# STM32WB5Mxx register map
File version: 1.0
Registers are 32-bit, read-write, reset 0x0 unless marked. A register's access mark holds for its fields unless they carry their own. Offsets are from the block's base; [hi:lo] are bit positions; {n}, {i} and the like mark numbered series.

## PWR — Power Control
Base 0x58000400
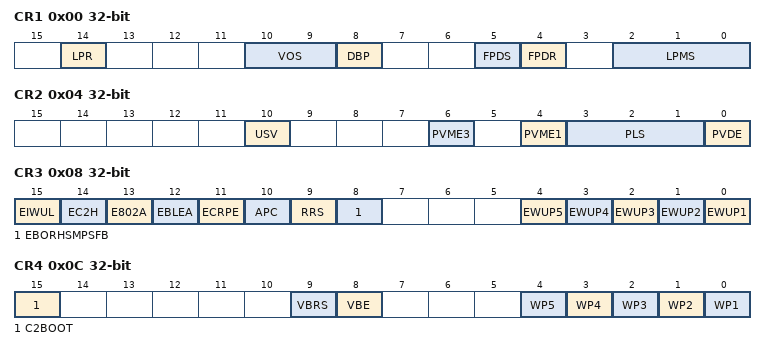
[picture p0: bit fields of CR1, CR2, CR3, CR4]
0x00 CR1 — PWR Power Control Register 1
  [14] LPR — Regulator Low-Power Run mode
  [10:9] VOS — Voltage scaling range selection
    1=SCALE1; 2=SCALE2
  [8] DBP — Disable Backup Domain write protection
  [5] FPDS — Flash power down mode during LPsleep for CPU1
    0=IDLE; 1=POWER_DOWN
  [4] FPDR — Flash power down mode during LPrun for CPU1
    0=IDLE; 1=POWER_DOWN
  [2:0] LPMS — Low Power Mode Selection for CPU1
    0=STOP0; 1=STOP1; 2=STOP2; 3=STANDBY; 4=SHUTDOWN
0x04 CR2 — PWR Power Control Register 2
  [10] USV — USB Supply Valid
  [6] PVME3 — Peripherical Voltage Monitor Vdda Enable
  [4] PVME1 — Peripherical Voltage Monitor Vusb Enable
  [3:1] PLS — Power voltage detector level selection
    {v}=PVDLEVEL_{v} (v=0..7)
  [0] PVDE — Power voltage detector enable
0x08 CR3 — PWR Power Control Register 3
  [15] EIWUL — Internal Wake-Up line interrupt for CPU1
  [14] EC2H — CPU2 Hold interrupt for CPU1
  [13] E802A — 802.15.4 end of activity interrupt for CPU1
  [12] EBLEA — BLE end of activity interrupt for CPU1
  [11] ECRPE — Critical radio phase end of activity interrupt for CPU1
  [10] APC — Apply pull-up and pull-down configuration for CPU1
  [9] RRS — SRAM2 retention in STANDBY mode
  [8] EBORHSMPSFB — BORH and SMPS Step Down converter forced in Bypass interrupts for CPU1
  [4] EWUP5 — Enable external WKUP Pin 5 [line 4]
  [3] EWUP4 — Enable external WKUP Pin 4 [line 3]
  [2] EWUP3 — Enable external WKUP Pin 3 [line 2]
  [1] EWUP2 — Enable external WKUP Pin 2 [line 1]
  [0] EWUP1 — Enable external WKUP Pin 1 [line 0]
0x0C CR4 — PWR Power Control Register 4
  [15] C2BOOT — Boot CPU2 after reset or wakeup from Stop or Standby modes
  [9] VBRS — VBAT battery charging resistor selection
    0=CHARG_RESISTOR_5K; 1=CHARGRESISTOR_1_5K
  [8] VBE — VBAT battery charging enable
  [4] WP5 — Wake-Up Pin 5 [line 4] polarity
  [3] WP4 — Wake-Up Pin 4 [line 3] polarity
  [2] WP3 — Wake-Up Pin 3 [line 2] polarity
  [1] WP2 — Wake-Up Pin 2 [line 1] polarity
  [0] WP1 — Wake-Up Pin 1 [line 0] polarity
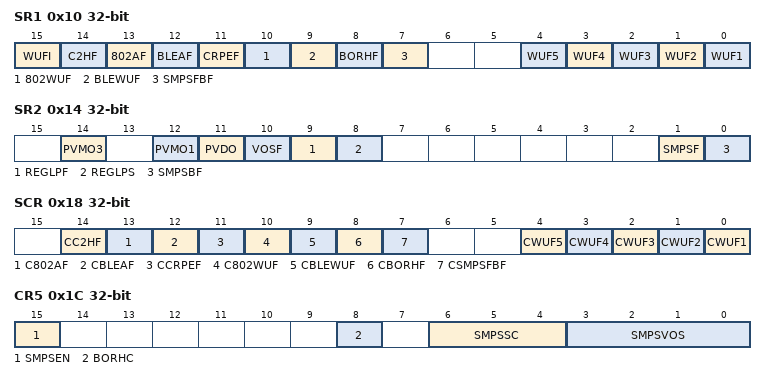
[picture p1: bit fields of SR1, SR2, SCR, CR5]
0x10 SR1 — PWR Power Status Register 1
  [15] WUFI — Internal wakeup interrupt flag
  [14] C2HF — CPU2 Hold interrupt flag
  [13] 802AF — 802.15.4 end of activity interrupt flag
  [12] BLEAF — BLE end of activity interrupt flag
  [11] CRPEF — Critical radio phase end of activity interrupt flag
  [10] 802WUF — 802.15.4 wakeup interrupt flag
  [9] BLEWUF — BLE wakeup interrupt flag
  [8] BORHF — BORH interrupt flag
  [7] SMPSFBF — SMPS Step Down converter forced in bypass mode interrupt flag
  [4] WUF5 — Wakeup Pin 5 [Flag 4]
  [3] WUF4 — Wakeup Pin 4 [Flag 3]
  [2] WUF3 — Wakeup Pin 3 [Flag 2]
  [1] WUF2 — Wakeup Pin 2 [Flag 1]
  [0] WUF1 — Wakeup Pin 1 [Flag 0]
0x14 SR2 — PWR Power Status Register 2
  [14] PVMO3 — Peripheral voltage monitor output 3: VDDA vs. 1.62V
  [12] PVMO1 — Peripheral voltage monitor output 1: VDDUSB vs. 1.2V
  [11] PVDO — Power voltage detector output
  [10] VOSF — Voltage scaling flag
  [9] REGLPF — Low-power regulator flag
  [8] REGLPS — Low-power regulator started
  [1] SMPSF — SMPS step down converter in operating mode step down flag
  [0] SMPSBF — SMPS step down converter in operating mode bypass flag
0x18 SCR — PWR Power Status Reset Register
  [14] CC2HF — Clear CPU2 Hold interrupt flag
  [13] C802AF — Clear 802.15.4 end of activity interrupt flag
  [12] CBLEAF — Clear BLE end of activity interrupt flag
  [11] CCRPEF — Clear Critical radio phase end of activity interrupt flag
  [10] C802WUF — Clear 802.15.4 wakeup interrupt flag
  [9] CBLEWUF — Clear BLE wakeup interrupt flag
  [8] CBORHF — Clear BORH interrupt flag
  [7] CSMPSFBF — Clear SMPS Step Down converter forced in bypass mode interrupt flag
  [4] CWUF5 — Clear Wake-up Pin 5 [Flag 4]
  [3] CWUF4 — Clear Wake-up Pin 4 [Flag 3]
  [2] CWUF3 — Clear Wake-up Pin 3 [Flag 2]
  [1] CWUF2 — Clear Wake-up Pin 2 [Flag 1]
  [0] CWUF1 — Clear Wake-up Pin 1 [Flag 0]
0x1C CR5 — PWR Power Control Register 5
  [15] SMPSEN — Enable SMPS Step Down converter SMPS mode enable
  [8] BORHC — BORH configuration selection
    0=SYSTEM_RESET (BOR will generate a system reset); 1=SMPS_FORCE_BYPASS (BOR will for SMPS step down converter in bypass mode)
  [6:4] SMPSSC — SMPS step down converter supply startup current selection
    0=CURRENT_80MA (SMPS step down converter supply startup current 80mA); 1=CURRENT_100MA (SMPS step down converter supply startup current 100mA); 2=CURRENT_120MA (SMPS step down converter supply startup current 120mA); 3=CURRENT_140MA (SMPS step down converter supply startup current 140mA); 4=CURRENT_160MA (SMPS step down converter supply startup current 160mA); 5=CURRENT_180MA (SMPS step down converter supply startup current 180mA); 6=CURRENT_200MA (SMPS step down converter supply startup current 200mA); 7=CURRENT_220MA (SMPS step down converter supply startup current 220mA)
  [3:0] SMPSVOS — SMPS step down converter voltage output scaling voltage level
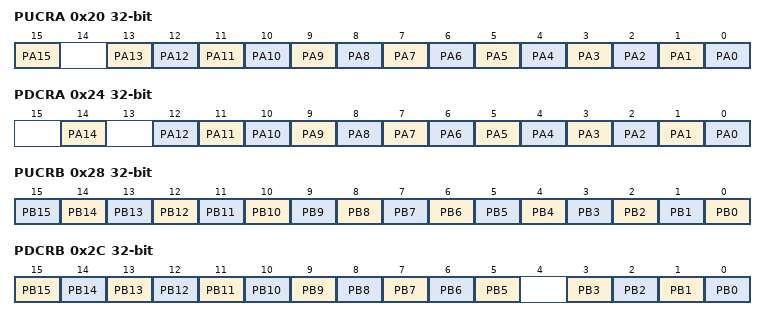
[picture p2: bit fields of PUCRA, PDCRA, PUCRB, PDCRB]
0x20 PUCRA — PWR Pull-Up Control Register of port A
  [15] PA15 — Pin PA15 Pull-Up set
  [n] PA{n} (n=0..13) — Pin PA{n} Pull-Up set
0x24 PDCRA — PWR Pull-Down Control Register of port A
  [14] PA14 — Pin PA14 Pull-Down set
  [n] PA{n} (n=0..12) — Pin PA{n} Pull-Down set
0x28 PUCRB — PWR Pull-Up Control Register of port B
  [n] PB{n} (n=0..15) — Pin PB{n} Pull-Up set
0x2C PDCRB — PWR Pull-Down Control Register of port B
  [n] PB{n} (n=5..15) — Pin PB{n} Pull-Down set
  [n] PB{n} (n=0..3) — Pin PB{n} Pull-Down set
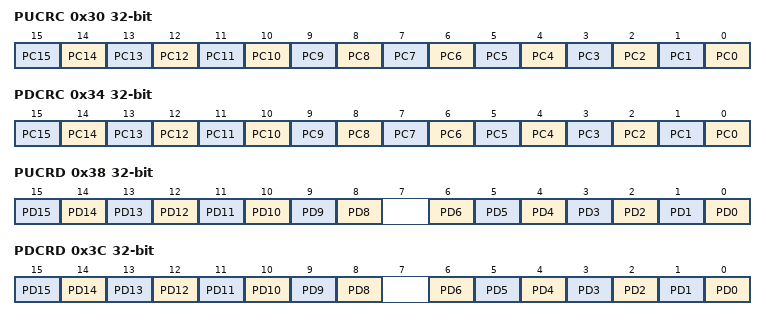
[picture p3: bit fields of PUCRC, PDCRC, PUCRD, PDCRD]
0x30 PUCRC — PWR Pull-Up Control Register of port C
  [n] PC{n} (n=0..15) — Pin PC{n} Pull-Up set
0x34 PDCRC — PWR Pull-Down Control Register of port C
  [n] PC{n} (n=0..15) — Pin PC{n} Pull-Down set
0x38 PUCRD — PWR Pull-Up Control Register of port D
  [n] PD{n} (n=8..15) — Pin PD{n} Pull-Up set
  [n] PD{n} (n=0..6) — Pin PD{n} Pull-Up set
0x3C PDCRD — PWR Pull-Down Control Register of port D
  [n] PD{n} (n=8..15) — Pin PD{n} Pull-Down set
  [n] PD{n} (n=0..6) — Pin PD{n} Pull-Down set
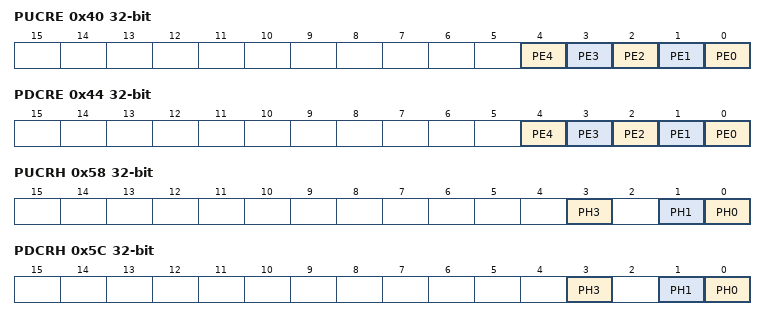
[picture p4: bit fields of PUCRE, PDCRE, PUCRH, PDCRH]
0x40 PUCRE — PWR Pull-Up Control Register of port E
  [n] PE{n} (n=0..4) — Pin PE{n} Pull-Up set
0x44 PDCRE — PWR Pull-Down Control Register of port E
  [n] PE{n} (n=0..4) — Pin PE{n} Pull-Down set
0x58 PUCRH — PWR Pull-Up Control Register of port H
  [3] PH3 — Pin PH3 Pull-Up set
  [1] PH1 — Pin PH1 Pull-Up set
  [0] PH0 — Pin PH0 Pull-Up set
0x5C PDCRH — PWR Pull-Down Control Register of port H
  [3] PH3 — Pin PH3 Pull-Down set
  [1] PH1 — Pin PH1 Pull-Down set
  [0] PH0 — Pin PH0 Pull-Down set
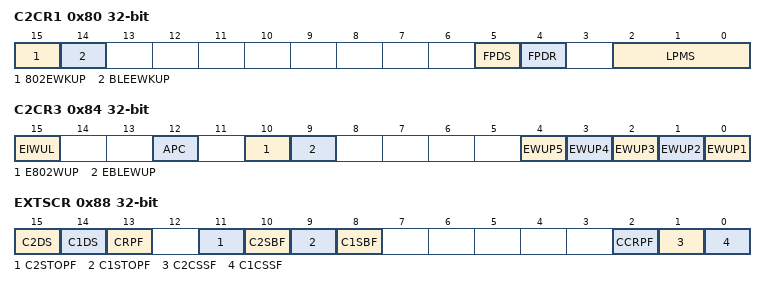
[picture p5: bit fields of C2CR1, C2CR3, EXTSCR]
0x80 C2CR1 — PWR Power Control Register 1 for CPU2
  [15] 802EWKUP — Radio 802.15.4 external wakeup signal
  [14] BLEEWKUP — Radio BLE external wakeup signal
  [5] FPDS — Flash power down mode during LPsleep for CPU2
    0=IDLE; 1=POWER_DOWN
  [4] FPDR — Flash power down mode during LPrun for CPU2
    0=IDLE; 1=POWER_DOWN
  [2:0] LPMS — Low Power Mode Selection for CPU2
    0=STOP0; 1=STOP1; 2=STOP2; 3=STANDBY; 4=SHUTDOWN
0x84 C2CR3 — PWR Power Control Register 3 for CPU2
  [15] EIWUL — Internal Wake-Up line interrupt for CPU2
  [12] APC — Apply pull-up and pull-down configuration for CPU2
  [10] E802WUP — Enable BLE host wakeup interrupt for CPU2
  [9] EBLEWUP — Enable BLE host wakeup interrupt for CPU2
  [4] EWUP5 — Enable external WKUP Pin 5 [line 4] for CPU2
  [3] EWUP4 — Enable external WKUP Pin 4 [line 3] for CPU2
  [2] EWUP3 — Enable external WKUP Pin 3 [line 2] for CPU2
  [1] EWUP2 — Enable external WKUP Pin 2 [line 1] for CPU2
  [0] EWUP1 — Enable external WKUP Pin 1 [line 0] for CPU2
0x88 EXTSCR — PWR Power Status Reset Register for CPU2
  [15] C2DS — CPU2 deepsleep mode flag
  [14] C1DS — CPU1 deepsleep mode flag
  [13] CRPF — Critical radio system phase flag
  [11] C2STOPF — System stop flag for CPU2
  [10] C2SBF — System standby flag for CPU2
  [9] C1STOPF — System stop flag for CPU1
  [8] C1SBF — System standby flag for CPU1
  [2] CCRPF — Clear critical radio system phase flag
  [1] C2CSSF — Clear standby and stop flags for CPU2
  [0] C1CSSF — Clear standby and stop flags for CPU1
